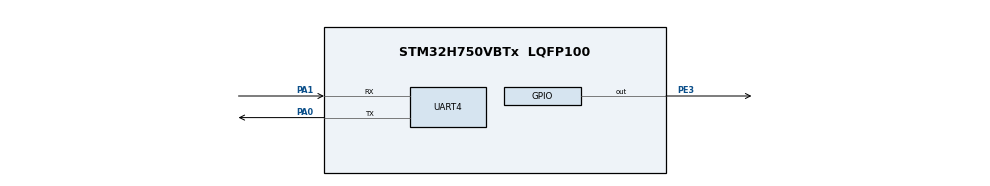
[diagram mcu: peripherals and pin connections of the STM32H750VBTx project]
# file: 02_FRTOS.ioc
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CORTEX_M7.CPU_ICache=Disabled
FREERTOS.Tasks01=defaultTask,24,128,StartDefaultTask,Default,NULL,Dynamic,NULL,NULL
Mcu.Family=STM32H7
Mcu.Name=STM32H750VBTx
Mcu.Package=LQFP100
NVIC.PriorityGroup=NVIC_PRIORITYGROUP_4
NVIC.TIM1_UP_IRQn=true\:15\:0\:false\:false\:true\:false\:false\:true\:true
NVIC.TimeBase=TIM1_UP_IRQn
NVIC.TimeBaseIP=TIM1
PA0.Mode=Asynchronous
PA0.Signal=UART4_TX
PA1.Mode=Asynchronous
PA1.Signal=UART4_RX
PA13\ (JTMS/SWDIO).Mode=Serial_Wire
PA13\ (JTMS/SWDIO).Signal=DEBUG_JTMS-SWDIO
PA14\ (JTCK/SWCLK).Mode=Serial_Wire
PA14\ (JTCK/SWCLK).Signal=DEBUG_JTCK-SWCLK
PE3.Signal=GPIO_Output
ProjectManager.HeapSize=0x1000
ProjectManager.StackSize=0x400
ProjectManager.TargetToolchain=MDK-ARM V5.27
RCC.ADCFreq_Value=129000000
RCC.APB1Freq_Value=32000000
RCC.APB2Freq_Value=64000000
RCC.APB3Freq_Value=64000000
RCC.APB4Freq_Value=64000000
RCC.CortexFreq_Value=64000000
RCC.D2PPRE1=RCC_APB1_DIV2
RCC.HCLKFreq_Value=64000000
RCC.SYSCLKFreq_VALUE=64000000
RCC.USBFreq_Value=129000000
VP_FREERTOS_VS_CMSIS_V2.Mode=CMSIS_V2
VP_SYS_VS_tim1.Mode=TIM1
board=custom

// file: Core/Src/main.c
/* USER CODE BEGIN Header */
/**
  ******************************************************************************
  * @file           : main.c
  * @brief          : Main program body
  ******************************************************************************
  * @attention
  *
  * Copyright (c) 2022 STMicroelectronics.
  * All rights reserved.
  *
  * This software is licensed under terms that can be found in the LICENSE file
  * in the root directory of this software component.
  * If no LICENSE file comes with this software, it is provided AS-IS.
  *
  ******************************************************************************
  */
/* USER CODE END Header */
#include "main.h"
#include "cmsis_os.h"
#include "usart.h"
#include "gpio.h"

/* USER CODE BEGIN Includes */
#include "stdio.h"
#include "task_entry.h"
#include "EventRecorder.h"
/* USER CODE END Includes */

void SystemClock_Config(void);
void MX_FREERTOS_Init(void);

int main(void)
{

  /* MCU Configuration--------------------------------------------------------*/

  /* Reset of all peripherals, Initializes the Flash interface and the Systick. */
  HAL_Init();

  /* Configure the system clock */
  SystemClock_Config();

  /* Initialize all configured peripherals */
  MX_GPIO_Init();
  MX_UART4_Init();
  /* USER CODE BEGIN 2 */
	EventRecorderInitialize(EventRecordAll, 0);
	EventRecorderDisable(EventRecordError ^ EventRecordAll, 0xFE, 0xFE);
	EventRecorderStart();
  /* USER CODE END 2 */

  /* Init scheduler */
  osKernelInitialize();  /* Call init function for freertos objects (in freertos.c) */
  MX_FREERTOS_Init();

  /* Start scheduler */
  osKernelStart();

  /* We should never get here as control is now taken by the scheduler */
  /* Infinite loop */
  while (1)
  {

  }
}

void SystemClock_Config(void)
{
  RCC_OscInitTypeDef RCC_OscInitStruct = {0};
  RCC_ClkInitTypeDef RCC_ClkInitStruct = {0};

  /** Supply configuration update enable
  */
  HAL_PWREx_ConfigSupply(PWR_LDO_SUPPLY);

  /** Configure the main internal regulator output voltage
  */
  __HAL_PWR_VOLTAGESCALING_CONFIG(PWR_REGULATOR_VOLTAGE_SCALE3);

  while(!__HAL_PWR_GET_FLAG(PWR_FLAG_VOSRDY)) {}

  /** Initializes the RCC Oscillators according to the specified parameters
  * in the RCC_OscInitTypeDef structure.
  */
  RCC_OscInitStruct.OscillatorType = RCC_OSCILLATORTYPE_HSI;
  RCC_OscInitStruct.HSIState = RCC_HSI_DIV1;
  RCC_OscInitStruct.HSICalibrationValue = RCC_HSICALIBRATION_DEFAULT;
  RCC_OscInitStruct.PLL.PLLState = RCC_PLL_NONE;
  if (HAL_RCC_OscConfig(&RCC_OscInitStruct) != HAL_OK)
  {
    Error_Handler();
  }

  /** Initializes the CPU, AHB and APB buses clocks
  */
  RCC_ClkInitStruct.ClockType = RCC_CLOCKTYPE_HCLK|RCC_CLOCKTYPE_SYSCLK
                              |RCC_CLOCKTYPE_PCLK1|RCC_CLOCKTYPE_PCLK2
                              |RCC_CLOCKTYPE_D3PCLK1|RCC_CLOCKTYPE_D1PCLK1;
  RCC_ClkInitStruct.SYSCLKSource = RCC_SYSCLKSOURCE_HSI;
  RCC_ClkInitStruct.SYSCLKDivider = RCC_SYSCLK_DIV1;
  RCC_ClkInitStruct.AHBCLKDivider = RCC_HCLK_DIV1;
  RCC_ClkInitStruct.APB3CLKDivider = RCC_APB3_DIV1;
  RCC_ClkInitStruct.APB1CLKDivider = RCC_APB1_DIV2;
  RCC_ClkInitStruct.APB2CLKDivider = RCC_APB2_DIV1;
  RCC_ClkInitStruct.APB4CLKDivider = RCC_APB4_DIV1;

  if (HAL_RCC_ClockConfig(&RCC_ClkInitStruct, FLASH_LATENCY_1) != HAL_OK)
  {
    Error_Handler();
  }
}

void HAL_TIM_PeriodElapsedCallback(TIM_HandleTypeDef *htim)
{
  if (htim->Instance == TIM1) {
    HAL_IncTick();
  }
}

void Error_Handler(void)
{
  __disable_irq();
  while (1)
  {
  }
}

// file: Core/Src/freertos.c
/* USER CODE BEGIN Header */
/**
  ******************************************************************************
  * File Name          : freertos.c
  * Description        : Code for freertos applications
  ******************************************************************************
  * @attention
  *
  * Copyright (c) 2022 STMicroelectronics.
  * All rights reserved.
  *
  * This software is licensed under terms that can be found in the LICENSE file
  * in the root directory of this software component.
  * If no LICENSE file comes with this software, it is provided AS-IS.
  *
  ******************************************************************************
  */
/* USER CODE END Header */

#include "FreeRTOS.h"
#include "task.h"
#include "main.h"
#include "cmsis_os.h"

/* USER CODE BEGIN Includes */
#include "stdio.h"
#include "EventRecorder.h"
/* USER CODE END Includes */

/* Definitions for defaultTask */
osThreadId_t defaultTaskHandle;
const osThreadAttr_t defaultTask_attributes = {
  .name = "defaultTask",
  .stack_size = 128 * 4,
  .priority = (osPriority_t) osPriorityNormal,
};

void StartDefaultTask(void *argument);

void MX_FREERTOS_Init(void); /* (MISRA C 2004 rule 8.1) */

void MX_FREERTOS_Init(void) {

  /* Create the thread(s) */
  /* creation of defaultTask */
  defaultTaskHandle = osThreadNew(StartDefaultTask, NULL, &defaultTask_attributes);

}

void StartDefaultTask(void *argument)
{
  /* USER CODE BEGIN StartDefaultTask */
	uint32_t start_time = xTaskGetTickCount();
  /* Infinite loop */
  for(;;)
  {

		HAL_GPIO_TogglePin(GPIOE, GPIO_PIN_3);
		EventRecord2(0x0000, start_time, 0);
    vTaskDelayUntil(&start_time, 500);
  }
  /* USER CODE END StartDefaultTask */
}
